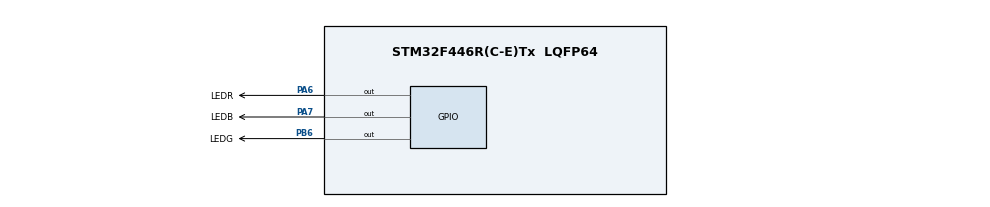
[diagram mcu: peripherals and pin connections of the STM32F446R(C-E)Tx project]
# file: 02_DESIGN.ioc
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Mcu.Family=STM32F4
Mcu.Name=STM32F446R(C-E)Tx
Mcu.Package=LQFP64
NVIC.PriorityGroup=NVIC_PRIORITYGROUP_4
NVIC.TIM1_UP_TIM10_IRQn=true\:0\:0\:false\:false\:true\:true\:true\:true
PA6.GPIO_Label=LEDR
PA6.GPIO_ModeDefaultOutputPP=GPIO_MODE_OUTPUT_PP
PA6.GPIO_PuPd=GPIO_NOPULL
PA6.GPIO_Speed=GPIO_SPEED_FREQ_LOW
PA6.PinState=GPIO_PIN_RESET
PA6.Signal=GPIO_Output
PA7.GPIO_Label=LEDB
PA7.GPIO_ModeDefaultOutputPP=GPIO_MODE_OUTPUT_PP
PA7.GPIO_PuPd=GPIO_NOPULL
PA7.GPIO_Speed=GPIO_SPEED_FREQ_LOW
PA7.PinState=GPIO_PIN_RESET
PA7.Signal=GPIO_Output
PB6.GPIO_Label=LEDG
PB6.GPIO_ModeDefaultOutputPP=GPIO_MODE_OUTPUT_PP
PB6.GPIO_PuPd=GPIO_NOPULL
PB6.GPIO_Speed=GPIO_SPEED_FREQ_LOW
PB6.PinState=GPIO_PIN_RESET
PB6.Signal=GPIO_Output
ProjectManager.HeapSize=0x200
ProjectManager.StackSize=0x400
ProjectManager.TargetToolchain=SW4STM32
RCC.CortexFreq_Value=16000000
RCC.USBFreq_Value=96000000
RCC.VCOOutputFreq_Value=192000000
TIM1.Period=499
TIM1.Prescaler=15999
VP_TIM1_VS_ClockSourceINT.Mode=Internal
board=custom

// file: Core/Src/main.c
/* USER CODE BEGIN Header */
/**
  ******************************************************************************
  * @file           : main.c
  * @brief          : Main program body
  ******************************************************************************
  * @attention
  *
  * Copyright (c) 2025 STMicroelectronics.
  * All rights reserved.
  *
  * This software is licensed under terms that can be found in the LICENSE file
  * in the root directory of this software component.
  * If no LICENSE file comes with this software, it is provided AS-IS.
  *
  ******************************************************************************
  */
/* USER CODE END Header */
#include "main.h"

 TIM_HandleTypeDef htim1;

/* USER CODE BEGIN PV */
volatile uint32_t cnt = 0;
/* USER CODE END PV */

void SystemClock_Config(void);
static void MX_GPIO_Init(void);
static void MX_TIM1_Init(void);

int main(void)
{

  /* MCU Configuration--------------------------------------------------------*/

  /* Reset of all peripherals, Initializes the Flash interface and the Systick. */
  HAL_Init();

  /* Configure the system clock */
  SystemClock_Config();

  /* Initialize all configured peripherals */
  MX_GPIO_Init();
  MX_TIM1_Init();
  /* USER CODE BEGIN 2 */
  HAL_TIM_Base_Start_IT(&htim1);
  /* USER CODE END 2 */

  /* Infinite loop */
  while (1)
  {

  }
}

void SystemClock_Config(void)
{
  RCC_OscInitTypeDef RCC_OscInitStruct = {0};
  RCC_ClkInitTypeDef RCC_ClkInitStruct = {0};

  /** Configure the main internal regulator output voltage
  */
  __HAL_RCC_PWR_CLK_ENABLE();
  __HAL_PWR_VOLTAGESCALING_CONFIG(PWR_REGULATOR_VOLTAGE_SCALE3);

  /** Initializes the RCC Oscillators according to the specified parameters
  * in the RCC_OscInitTypeDef structure.
  */
  RCC_OscInitStruct.OscillatorType = RCC_OSCILLATORTYPE_HSI;
  RCC_OscInitStruct.HSIState = RCC_HSI_ON;
  RCC_OscInitStruct.HSICalibrationValue = RCC_HSICALIBRATION_DEFAULT;
  RCC_OscInitStruct.PLL.PLLState = RCC_PLL_NONE;
  if (HAL_RCC_OscConfig(&RCC_OscInitStruct) != HAL_OK)
  {
    Error_Handler();
  }

  /** Initializes the CPU, AHB and APB buses clocks
  */
  RCC_ClkInitStruct.ClockType = RCC_CLOCKTYPE_HCLK|RCC_CLOCKTYPE_SYSCLK
                              |RCC_CLOCKTYPE_PCLK1|RCC_CLOCKTYPE_PCLK2;
  RCC_ClkInitStruct.SYSCLKSource = RCC_SYSCLKSOURCE_HSI;
  RCC_ClkInitStruct.AHBCLKDivider = RCC_SYSCLK_DIV1;
  RCC_ClkInitStruct.APB1CLKDivider = RCC_HCLK_DIV1;
  RCC_ClkInitStruct.APB2CLKDivider = RCC_HCLK_DIV1;

  if (HAL_RCC_ClockConfig(&RCC_ClkInitStruct, FLASH_LATENCY_0) != HAL_OK)
  {
    Error_Handler();
  }
}

static void MX_TIM1_Init(void)
{

  TIM_ClockConfigTypeDef sClockSourceConfig = {0};
  TIM_MasterConfigTypeDef sMasterConfig = {0};

  htim1.Instance = TIM1;
  htim1.Init.Prescaler = 15999;
  htim1.Init.CounterMode = TIM_COUNTERMODE_UP;
  htim1.Init.Period = 499;
  htim1.Init.ClockDivision = TIM_CLOCKDIVISION_DIV1;
  htim1.Init.RepetitionCounter = 0;
  htim1.Init.AutoReloadPreload = TIM_AUTORELOAD_PRELOAD_DISABLE;
  if (HAL_TIM_Base_Init(&htim1) != HAL_OK)
  {
    Error_Handler();
  }
  sClockSourceConfig.ClockSource = TIM_CLOCKSOURCE_INTERNAL;
  if (HAL_TIM_ConfigClockSource(&htim1, &sClockSourceConfig) != HAL_OK)
  {
    Error_Handler();
  }
  sMasterConfig.MasterOutputTrigger = TIM_TRGO_RESET;
  sMasterConfig.MasterSlaveMode = TIM_MASTERSLAVEMODE_DISABLE;
  if (HAL_TIMEx_MasterConfigSynchronization(&htim1, &sMasterConfig) != HAL_OK)
  {
    Error_Handler();
  }

}

static void MX_GPIO_Init(void)
{
  GPIO_InitTypeDef GPIO_InitStruct = {0};

  /* GPIO Ports Clock Enable */
  __HAL_RCC_GPIOA_CLK_ENABLE();
  __HAL_RCC_GPIOB_CLK_ENABLE();

  /*Configure GPIO pin Output Level */
  HAL_GPIO_WritePin(GPIOA, GPIO_PIN_6|GPIO_PIN_7, GPIO_PIN_RESET);

  /*Configure GPIO pin Output Level */
  HAL_GPIO_WritePin(GPIOB, GPIO_PIN_6, GPIO_PIN_RESET);

  /*Configure GPIO pins : PA6 PA7 */
  GPIO_InitStruct.Pin = GPIO_PIN_6|GPIO_PIN_7;
  GPIO_InitStruct.Mode = GPIO_MODE_OUTPUT_PP;
  GPIO_InitStruct.Pull = GPIO_NOPULL;
  GPIO_InitStruct.Speed = GPIO_SPEED_FREQ_LOW;
  HAL_GPIO_Init(GPIOA, &GPIO_InitStruct);

  /*Configure GPIO pin : PB6 */
  GPIO_InitStruct.Pin = GPIO_PIN_6;
  GPIO_InitStruct.Mode = GPIO_MODE_OUTPUT_PP;
  GPIO_InitStruct.Pull = GPIO_NOPULL;
  GPIO_InitStruct.Speed = GPIO_SPEED_FREQ_LOW;
  HAL_GPIO_Init(GPIOB, &GPIO_InitStruct);

}

/* USER CODE BEGIN 4 */
void HAL_TIM_PeriodElapsedCallback(TIM_HandleTypeDef *htim)
{
  if (htim->Instance == TIM1)
  {
    if (cnt >= 0 && cnt <= 7) // red light
    {
      HAL_GPIO_WritePin(LEDR_GPIO_Port, LEDR_Pin, GPIO_PIN_SET);
      HAL_GPIO_WritePin(LEDG_GPIO_Port, LEDG_Pin, GPIO_PIN_RESET);
      HAL_GPIO_WritePin(LEDB_GPIO_Port, LEDB_Pin, GPIO_PIN_RESET);
    }
    else if (cnt >= 8 && cnt <= 11 ) //green light
    {
      HAL_GPIO_WritePin(LEDR_GPIO_Port, LEDR_Pin, GPIO_PIN_RESET);
      HAL_GPIO_WritePin(LEDG_GPIO_Port, LEDG_Pin, GPIO_PIN_SET);
      HAL_GPIO_WritePin(LEDB_GPIO_Port, LEDB_Pin, GPIO_PIN_RESET);
    }
    else if (cnt ==12 ) //no light
    {
      HAL_GPIO_WritePin(LEDR_GPIO_Port, LEDR_Pin, GPIO_PIN_RESET);
      HAL_GPIO_WritePin(LEDG_GPIO_Port, LEDG_Pin, GPIO_PIN_RESET);
      HAL_GPIO_WritePin(LEDB_GPIO_Port, LEDB_Pin, GPIO_PIN_RESET);
    }
    else if (cnt ==13 ) //green light
    {
      HAL_GPIO_WritePin(LEDR_GPIO_Port, LEDR_Pin, GPIO_PIN_RESET);
      HAL_GPIO_WritePin(LEDG_GPIO_Port, LEDG_Pin, GPIO_PIN_SET);
      HAL_GPIO_WritePin(LEDB_GPIO_Port, LEDB_Pin, GPIO_PIN_RESET);
    }
    else if (cnt ==14 ) //no light
    {
      HAL_GPIO_WritePin(LEDR_GPIO_Port, LEDR_Pin, GPIO_PIN_RESET);
      HAL_GPIO_WritePin(LEDG_GPIO_Port, LEDG_Pin, GPIO_PIN_RESET);
      HAL_GPIO_WritePin(LEDB_GPIO_Port, LEDB_Pin, GPIO_PIN_RESET);
    }
    else if (cnt ==15 ) //green light
    {
      HAL_GPIO_WritePin(LEDR_GPIO_Port, LEDR_Pin, GPIO_PIN_RESET);
      HAL_GPIO_WritePin(LEDG_GPIO_Port, LEDG_Pin, GPIO_PIN_SET);
      HAL_GPIO_WritePin(LEDB_GPIO_Port, LEDB_Pin, GPIO_PIN_RESET);
    }
    else if (cnt >= 16 && cnt <= 17 ) //yellow light
    {
      HAL_GPIO_WritePin(LEDR_GPIO_Port, LEDR_Pin, GPIO_PIN_SET);
      HAL_GPIO_WritePin(LEDG_GPIO_Port, LEDG_Pin, GPIO_PIN_SET);
      HAL_GPIO_WritePin(LEDB_GPIO_Port, LEDB_Pin, GPIO_PIN_RESET);
    }

    cnt++;
    cnt = cnt % 18;
  }
}
/* USER CODE END 4 */

void Error_Handler(void)
{
  __disable_irq();
  while (1)
  {
  }
}
